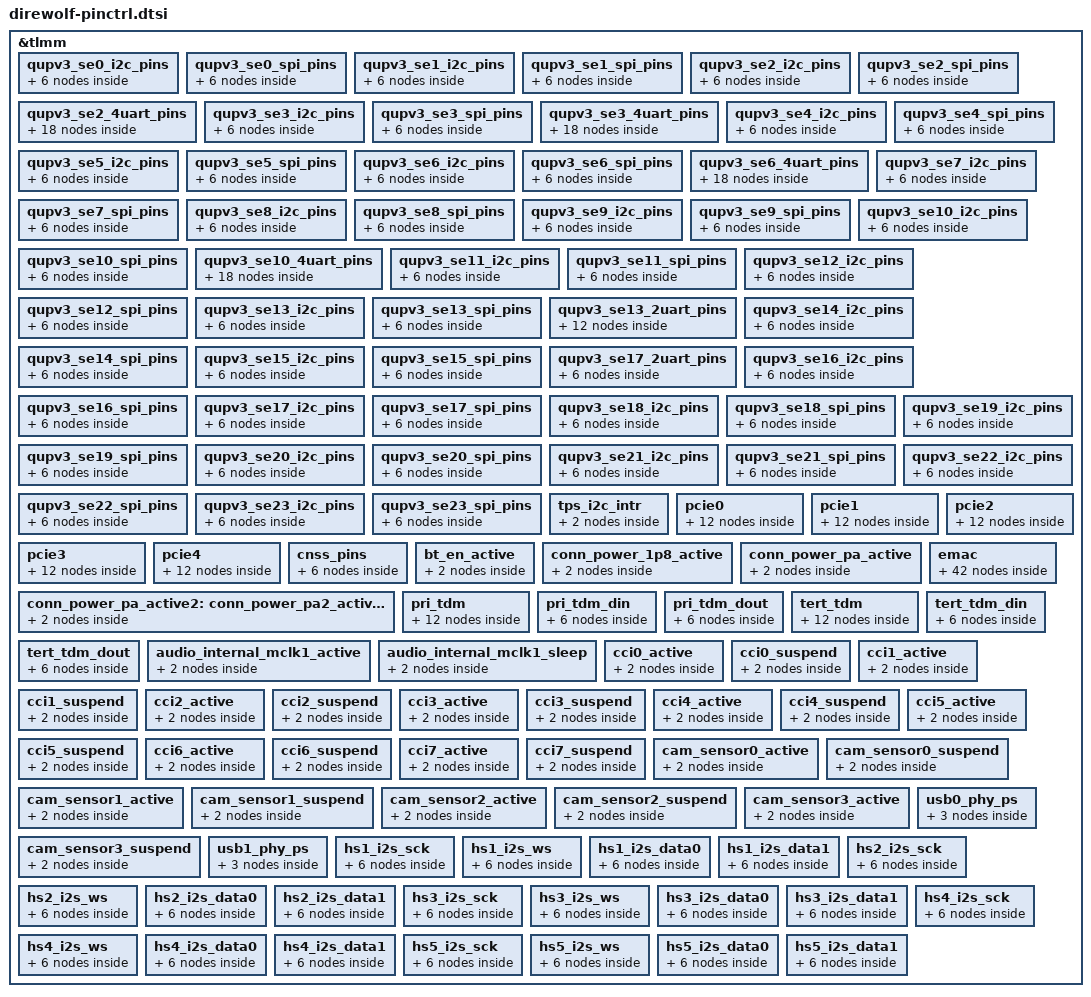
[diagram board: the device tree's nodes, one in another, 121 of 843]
&tlmm {
	qupv3_se0_i2c_pins: qupv3_se0_i2c_pins {
		qupv3_se0_i2c_active: qupv3_se0_i2c_active {
			mux {
				pins = "gpio135", "gpio136";
				function = "qup0";
			};

			config {
				pins = "gpio135", "gpio136";
				drive-strength = <2>;
				bias-pull-up;
			};
		};

		qupv3_se0_i2c_sleep: qupv3_se0_i2c_sleep {
			mux {
				pins = "gpio135", "gpio136";
				function = "gpio";
			};

			config {
				pins = "gpio135", "gpio136";
				drive-strength = <2>;
				bias-disable;
			};
		};
	};

	qupv3_se0_spi_pins: qupv3_se0_spi_pins {
		qupv3_se0_spi_active: qupv3_se0_spi_active {
			mux {
				pins = "gpio135", "gpio136",
						"gpio137", "gpio138";
				function = "qup0";
			};

			config {
				pins = "gpio135", "gpio136",
						"gpio137", "gpio138";
				drive-strength = <6>;
				bias-disable;
			};
		};

		qupv3_se0_spi_sleep: qupv3_se0_spi_sleep {
			mux {
				pins = "gpio135", "gpio136",
						"gpio137", "gpio138";
				function = "gpio";
			};

			config {
				pins = "gpio135", "gpio136",
						"gpio137", "gpio138";
				drive-strength = <6>;
				bias-disable;
			};
		};
	};

	qupv3_se1_i2c_pins: qupv3_se1_i2c_pins {
		qupv3_se1_i2c_active: qupv3_se1_i2c_active {
			mux {
				pins = "gpio158", "gpio159";
				function = "qup1";
			};

			config {
				pins = "gpio158", "gpio159";
				drive-strength = <2>;
				bias-pull-up;
			};
		};

		qupv3_se1_i2c_sleep: qupv3_se1_i2c_sleep {
			mux {
				pins = "gpio158", "gpio159";
				function = "gpio";
			};

			config {
				pins = "gpio158", "gpio159";
				drive-strength = <2>;
				bias-disable;
			};
		};
	};

	qupv3_se1_spi_pins: qupv3_se1_spi_pins {
		qupv3_se1_spi_active: qupv3_se1_spi_active {
			mux {
				pins = "gpio158", "gpio159",
						"gpio160", "gpio161";
				function = "qup1";
			};

			config {
				pins = "gpio158", "gpio159",
						"gpio160", "gpio161";
				drive-strength = <6>;
				bias-disable;
			};
		};

		qupv3_se1_spi_sleep: qupv3_se1_spi_sleep {
			mux {
				pins = "gpio158", "gpio159",
						"gpio160", "gpio161";
				function = "gpio";
			};

			config {
				pins = "gpio158", "gpio159",
						"gpio160", "gpio161";
				drive-strength = <6>;
				bias-disable;
			};
		};
	};

	qupv3_se2_i2c_pins: qupv3_se2_i2c_pins {
		qupv3_se2_i2c_active: qupv3_se2_i2c_active {
			mux {
				pins = "gpio121", "gpio122";
				function = "qup2";
			};

			config {
				pins = "gpio121", "gpio122";
				drive-strength = <2>;
				bias-pull-up;
			};
		};

		qupv3_se2_i2c_sleep: qupv3_se2_i2c_sleep {
			mux {
				pins = "gpio121", "gpio122";
				function = "gpio";
			};

			config {
				pins = "gpio121", "gpio122";
				drive-strength = <2>;
				bias-disable;
			};
		};
	};

	qupv3_se2_spi_pins: qupv3_se2_spi_pins {
		qupv3_se2_spi_active: qupv3_se2_spi_active {
			mux {
				pins = "gpio121", "gpio122",
						"gpio123", "gpio124";
				function = "qup2";
			};

			config {
				pins = "gpio121", "gpio122",
						"gpio123", "gpio124";
				drive-strength = <6>;
				bias-disable;
			};
		};

		qupv3_se2_spi_sleep: qupv3_se2_spi_sleep {
			mux {
				pins = "gpio121", "gpio122",
						"gpio123", "gpio124";
				function = "gpio";
			};

			config {
				pins = "gpio121", "gpio122",
						"gpio123", "gpio124";
				drive-strength = <6>;
				bias-disable;
			};
		};
	};

	qupv3_se2_4uart_pins: qupv3_se2_4uart_pins {
		qupv3_se2_default_cts:
				qupv3_se2_default_cts {
			mux {
				pins = "gpio121";
				function = "gpio";
			};

			config {
				pins = "gpio121";
				drive-strength = <2>;
				bias-disable;
			};
		};

		qupv3_se2_default_rtsrx:
			qupv3_se2_default_rtsrx {
			mux {
				pins = "gpio122", "gpio124";
				function = "gpio";
			};

			config {
				pins = "gpio122", "gpio124";
				drive-strength = <2>;
				bias-pull-down;
			};
		};

		qupv3_se2_default_tx:
			qupv3_se2_default_tx {
			mux {
				pins = "gpio123";
				function = "gpio";
			};

			config {
				pins = "gpio123";
				drive-strength = <2>;
				bias-pull-up;
			};
		};

		qupv3_se2_ctsrx: qupv3_se2_ctsrx {
			mux {
				pins = "gpio121", "gpio124";
				function = "qup2";
			};

			config {
				pins = "gpio121", "gpio124";
				drive-strength = <2>;
				bias-disable;
			};
		};

		qupv3_se2_rts: qupv3_se2_rts {
			mux {
				pins = "gpio122";
				function = "qup2";
			};

			config {
				pins = "gpio122";
				drive-strength = <2>;
				bias-pull-down;
			};
		};

		qupv3_se2_tx: qupv3_se2_tx {
			mux {
				pins = "gpio123";
				function = "qup2";
			};

			config {
				pins = "gpio123";
				drive-strength = <2>;
				bias-pull-up;
			};
		};
	};

	qupv3_se3_i2c_pins: qupv3_se3_i2c_pins {
		qupv3_se3_i2c_active: qupv3_se3_i2c_active {
			mux {
				pins = "gpio137", "gpio138";
				function = "qup3";
			};

			config {
				pins = "gpio137", "gpio138";
				drive-strength = <2>;
				bias-pull-up;
			};
		};

		qupv3_se3_i2c_sleep: qupv3_se3_i2c_sleep {
			mux {
				pins = "gpio137", "gpio138";
				function = "gpio";
			};

			config {
				pins = "gpio137", "gpio138";
				drive-strength = <2>;
				bias-disable;
			};
		};
	};

	qupv3_se3_spi_pins: qupv3_se3_spi_pins {
		qupv3_se3_spi_active: qupv3_se3_spi_active {
			mux {
				pins = "gpio137", "gpio138",
						"gpio135", "gpio136";
				function = "qup3";
			};

			config {
				pins = "gpio137", "gpio138",
						"gpio135", "gpio136";
				drive-strength = <6>;
				bias-disable;
			};
		};

		qupv3_se3_spi_sleep: qupv3_se3_spi_sleep {
			mux {
				pins = "gpio137", "gpio138",
						"gpio135", "gpio136";
				function = "gpio";
			};

			config {
				pins = "gpio137", "gpio138",
						"gpio135", "gpio136";
				drive-strength = <6>;
				bias-disable;
			};
		};
	};

	qupv3_se3_4uart_pins: qupv3_se3_4uart_pins {
		qupv3_se3_default_cts:
				qupv3_se3_default_cts {
			mux {
				pins = "gpio137";
				function = "gpio";
			};

			config {
				pins = "gpio137";
				drive-strength = <2>;
				bias-disable;
			};
		};

		qupv3_se3_default_rtsrx:
			qupv3_se3_default_rtsrx {
			mux {
				pins = "gpio138", "gpio136";
				function = "gpio";
			};

			config {
				pins = "gpio138", "gpio136";
				drive-strength = <2>;
				bias-pull-down;
			};
		};

		qupv3_se3_default_tx:
			qupv3_se3_default_tx {
			mux {
				pins = "gpio135";
				function = "gpio";
			};

			config {
				pins = "gpio135";
				drive-strength = <2>;
				bias-pull-up;
			};
		};

		qupv3_se3_ctsrx: qupv3_se3_ctsrx {
			mux {
				pins = "gpio137", "gpio136";
				function = "qup2";
			};

			config {
				pins = "gpio137", "gpio136";
				drive-strength = <2>;
				bias-disable;
			};
		};

		qupv3_se3_rts: qupv3_se3_rts {
			mux {
				pins = "gpio138";
				function = "qup2";
			};

			config {
				pins = "gpio138";
				drive-strength = <2>;
				bias-pull-down;
			};
		};

		qupv3_se3_tx: qupv3_se3_tx {
			mux {
				pins = "gpio135";
				function = "qup2";
			};

			config {
				pins = "gpio135";
				drive-strength = <2>;
				bias-pull-up;
			};
		};
	};

	qupv3_se4_i2c_pins: qupv3_se4_i2c_pins {
		qupv3_se4_i2c_active: qupv3_se4_i2c_active {
			mux {
				pins = "gpio171", "gpio172";
				function = "qup4";
			};

			config {
				pins = "gpio171", "gpio172";
				drive-strength = <2>;
				bias-pull-up;
			};
		};

		qupv3_se4_i2c_sleep: qupv3_se4_i2c_sleep {
			mux {
				pins = "gpio171", "gpio172";
				function = "gpio";
			};

			config {
				pins = "gpio171", "gpio172";
				drive-strength = <2>;
				bias-disable;
			};
		};
	};

	qupv3_se4_spi_pins: qupv3_se4_spi_pins {
		qupv3_se4_spi_active: qupv3_se4_spi_active {
			mux {
				pins = "gpio171", "gpio172",
						"gpio173", "gpio174";
				function = "qup4";
			};

			config {
				pins = "gpio171", "gpio172",
						"gpio173", "gpio174";
				drive-strength = <6>;
				bias-disable;
			};
		};

		qupv3_se4_spi_sleep: qupv3_se4_spi_sleep {
			mux {
				pins = "gpio171", "gpio172",
						"gpio173", "gpio174";
				function = "gpio";
			};

			config {
				pins = "gpio171", "gpio172",
						"gpio173", "gpio174";
				drive-strength = <6>;
				bias-disable;
			};
		};
	};

	qupv3_se5_i2c_pins: qupv3_se5_i2c_pins {
		qupv3_se5_i2c_active: qupv3_se5_i2c_active {
			mux {
				pins = "gpio111", "gpio112";
				function = "qup5";
			};

			config {
				pins = "gpio111", "gpio112";
				drive-strength = <2>;
				bias-pull-up;
			};
		};

		qupv3_se5_i2c_sleep: qupv3_se5_i2c_sleep {
			mux {
				pins = "gpio111", "gpio112";
				function = "gpio";
			};

			config {
				pins = "gpio111", "gpio112";
				drive-strength = <2>;
				bias-disable;
			};
		};
	};

	qupv3_se5_spi_pins: qupv3_se5_spi_pins {
		qupv3_se5_spi_active: qupv3_se5_spi_active {
			mux {
				pins = "gpio111", "gpio112",
						"gpio145", "gpio146";
				function = "qup5";
			};

			config {
				pins = "gpio111", "gpio112",
						"gpio145", "gpio146";
				drive-strength = <6>;
				bias-disable;
			};
		};

		qupv3_se5_spi_sleep: qupv3_se5_spi_sleep {
			mux {
				pins = "gpio111", "gpio112",
						"gpio145", "gpio146";
				function = "gpio";
			};

			config {
				pins = "gpio111", "gpio112",
						"gpio145", "gpio146";
				drive-strength = <6>;
				bias-disable;
			};
		};
	};

	qupv3_se6_i2c_pins: qupv3_se6_i2c_pins {
		qupv3_se6_i2c_active: qupv3_se6_i2c_active {
			mux {
				pins = "gpio154", "gpio155";
				function = "qup6";
			};

			config {
				pins = "gpio154", "gpio155";
				drive-strength = <2>;
				bias-pull-up;
			};
		};

		qupv3_se6_i2c_sleep: qupv3_se6_i2c_sleep {
			mux {
				pins = "gpio154", "gpio155";
				function = "gpio";
			};

			config {
				pins = "gpio154", "gpio155";
				drive-strength = <2>;
				bias-disable;
			};
		};
	};

	qupv3_se6_spi_pins: qupv3_se6_spi_pins {
		qupv3_se6_spi_active: qupv3_se6_spi_active {
			mux {
				pins = "gpio154", "gpio155",
						"gpio156", "gpio157";
				function = "qup6";
			};

			config {
				pins = "gpio154", "gpio155",
						"gpio156", "gpio157";
				drive-strength = <6>;
				bias-disable;
			};
		};

		qupv3_se6_spi_sleep: qupv3_se6_spi_sleep {
			mux {
				pins = "gpio154", "gpio155",
						"gpio156", "gpio157";
				function = "gpio";
			};

			config {
				pins = "gpio154", "gpio155",
						"gpio156", "gpio157";
				drive-strength = <6>;
				bias-disable;
			};
		};
	};

	qupv3_se6_4uart_pins: qupv3_se6_4uart_pins {
		qupv3_se6_default_cts:
			qupv3_se6_default_cts {
			mux {
				pins = "gpio154";
				function = "gpio";
			};

			config {
				pins = "gpio154";
				drive-strength = <2>;
				bias-disable;
			};
		};

		qupv3_se6_default_rtsrx:
			qupv3_se6_default_rtsrx {
			mux {
				pins = "gpio155", "gpio157";
				function = "gpio";
			};

			config {
				pins = "gpio155", "gpio157";
				drive-strength = <2>;
				bias-pull-down;
			};
		};

		qupv3_se6_default_tx:
			qupv3_se6_default_tx {
			mux {
				pins = "gpio156";
				function = "gpio";
			};

			config {
				pins = "gpio156";
				drive-strength = <2>;
				bias-pull-up;
			};
		};

		qupv3_se6_ctsrx: qupv3_se6_ctsrx {
			mux {
				pins = "gpio154", "gpio157";
				function = "qup6";
			};

			config {
				pins = "gpio154", "gpio157";
				drive-strength = <2>;
				bias-disable;
			};
		};

		qupv3_se6_rts: qupv3_se6_rts {
			mux {
				pins = "gpio155";
				function = "qup6";
			};

			config {
				pins = "gpio155";
				drive-strength = <2>;
				bias-pull-down;
			};
		};

		qupv3_se6_tx: qupv3_se6_tx {
			mux {
				pins = "gpio156";
				function = "qup6";
			};

			config {
				pins = "gpio156";
				drive-strength = <2>;
				bias-pull-up;
			};
		};
	};

	qupv3_se7_i2c_pins: qupv3_se7_i2c_pins {
		qupv3_se7_i2c_active: qupv3_se7_i2c_active {
			mux {
				pins = "gpio128", "gpio129";
				function = "qup7";
			};

			config {
				pins = "gpio128", "gpio129";
				drive-strength = <2>;
				bias-pull-up;
			};
		};

		qupv3_se7_i2c_sleep: qupv3_se7_i2c_sleep {
			mux {
				pins = "gpio128", "gpio129";
				function = "gpio";
			};

			config {
				pins = "gpio128", "gpio129";
				drive-strength = <2>;
				bias-disable;
			};
		};
	};

	qupv3_se7_spi_pins: qupv3_se7_spi_pins {
		qupv3_se7_spi_active: qupv3_se7_spi_active {
			mux {
				pins = "gpio128", "gpio129",
						"gpio125", "gpio126";
				function = "qup7";
			};

			config {
				pins = "gpio128", "gpio129",
						"gpio125", "gpio126";
				drive-strength = <6>;
				bias-disable;
			};
		};

		qupv3_se7_spi_sleep: qupv3_se7_spi_sleep {
			mux {
				pins = "gpio128", "gpio129",
						"gpio125", "gpio126";
				function = "gpio";
			};

			config {
				pins = "gpio128", "gpio129",
						"gpio125", "gpio126";
				drive-strength = <6>;
				bias-disable;
			};
		};
	};

	qupv3_se8_i2c_pins: qupv3_se8_i2c_pins {
		qupv3_se8_i2c_active: qupv3_se8_i2c_active {
			mux {
				pins = "gpio43", "gpio44";
				function = "qup8";
			};

			config {
				pins = "gpio43", "gpio44";
				drive-strength = <2>;
				bias-pull-up;
			};
		};

		qupv3_se8_i2c_sleep: qupv3_se8_i2c_sleep {
			mux {
				pins = "gpio43", "gpio44";
				function = "gpio";
			};

			config {
				pins = "gpio43", "gpio44";
				drive-strength = <2>;
				bias-disable;
			};
		};
	};

	qupv3_se8_spi_pins: qupv3_se8_spi_pins {
		qupv3_se8_spi_active: qupv3_se8_spi_active {
			mux {
				pins = "gpio43", "gpio44",
						"gpio45", "gpio46";
				function = "qup8";
			};

			config {
				pins = "gpio43", "gpio44",
						"gpio45", "gpio46";
				drive-strength = <6>;
				bias-disable;
			};
		};

		qupv3_se8_spi_sleep: qupv3_se8_spi_sleep {
			mux {
				pins = "gpio43", "gpio44",
						"gpio45", "gpio46";
				function = "gpio";
			};

			config {
				pins = "gpio43", "gpio44",
						"gpio45", "gpio46";
				drive-strength = <6>;
				bias-disable;
			};
		};
	};

	qupv3_se9_i2c_pins: qupv3_se9_i2c_pins {
		qupv3_se9_i2c_active: qupv3_se9_i2c_active {
			mux {
				pins = "gpio41", "gpio42";
				function = "qup9";
			};

			config {
				pins = "gpio41", "gpio42";
				drive-strength = <2>;
				bias-pull-up;
			};
		};

		qupv3_se9_i2c_sleep: qupv3_se9_i2c_sleep {
			mux {
				pins = "gpio41", "gpio42";
				function = "gpio";
			};

			config {
				pins = "gpio41", "gpio42";
				drive-strength = <2>;
				bias-disable;
			};
		};
	};

	qupv3_se9_spi_pins: qupv3_se9_spi_pins {
		qupv3_se9_spi_active: qupv3_se9_spi_active {
			mux {
				pins = "gpio41", "gpio42",
						"gpio43", "gpio44";
				function = "qup9";
			};

			config {
				pins = "gpio41", "gpio42",
						"gpio43", "gpio44";
				drive-strength = <6>;
				bias-disable;
			};
		};

		qupv3_se9_spi_sleep: qupv3_se9_spi_sleep {
			mux {
				pins = "gpio41", "gpio42",
						"gpio43", "gpio44";
				function = "gpio";
			};

			config {
				pins = "gpio41", "gpio42",
						"gpio43", "gpio44";
				drive-strength = <6>;
				bias-disable;
			};
		};
	};

	qupv3_se10_i2c_pins: qupv3_se10_i2c_pins {
		qupv3_se10_i2c_active: qupv3_se10_i2c_active {
			mux {
				pins = "gpio22", "gpio23";
				function = "qup10";
			};

			config {
				pins = "gpio22", "gpio23";
				drive-strength = <2>;
				bias-pull-up;
			};
		};

		qupv3_se10_i2c_sleep: qupv3_se10_i2c_sleep {
			mux {
				pins = "gpio22", "gpio23";
				function = "gpio";
			};

			config {
				pins = "gpio22", "gpio23";
				drive-strength = <2>;
				bias-disable;
			};
		};
	};

	qupv3_se10_spi_pins: qupv3_se10_spi_pins {
		qupv3_se10_spi_active: qupv3_se10_spi_active {
			mux {
				pins = "gpio22", "gpio23",
						"gpio24", "gpio25";
				function = "qup10";
			};

			config {
				pins = "gpio22", "gpio23",
						"gpio24", "gpio25";
				drive-strength = <6>;
				bias-disable;
			};
		};

		qupv3_se10_spi_sleep: qupv3_se10_spi_sleep {
			mux {
				pins = "gpio22", "gpio23",
						"gpio24", "gpio25";
				function = "gpio";
			};

			config {
				pins = "gpio22", "gpio23",
						"gpio24", "gpio25";
				drive-strength = <6>;
				bias-disable;
			};
		};
	};

	qupv3_se10_4uart_pins: qupv3_se10_4uart_pins {
		qupv3_se10_default_cts:
				qupv3_se10_default_cts {
			mux {
				pins = "gpio22";
				function = "gpio";
			};

			config {
				pins = "gpio22";
				drive-strength = <2>;
				bias-disable;
			};
		};

		qupv3_se10_default_rtsrx:
			qupv3_se10_default_rtsrx {
			mux {
				pins = "gpio23", "gpio25";
				function = "gpio";
			};

			config {
				pins = "gpio23", "gpio25";
				drive-strength = <2>;
				bias-pull-down;
			};
		};

		qupv3_se10_default_tx:
			qupv3_se10_default_tx {
			mux {
				pins = "gpio24";
				function = "gpio";
			};

			config {
				pins = "gpio24";
				drive-strength = <2>;
				bias-pull-up;
			};
		};

		qupv3_se10_ctsrx: qupv3_se10_ctsrx {
			mux {
				pins = "gpio22", "gpio25";
				function = "qup10";
			};

			config {
				pins = "gpio22", "gpio25";
				drive-strength = <2>;
				bias-disable;
			};
		};

		qupv3_se10_rts: qupv3_se10_rts {
			mux {
				pins = "gpio23";
				function = "qup10";
			};

			config {
				pins = "gpio23";
				drive-strength = <2>;
				bias-pull-down;
			};
		};

		qupv3_se10_tx: qupv3_se10_tx {
			mux {
				pins = "gpio24";
				function = "qup10";
			};

			config {
				pins = "gpio24";
				drive-strength = <2>;
				bias-pull-up;
			};
		};
	};

	qupv3_se11_i2c_pins: qupv3_se11_i2c_pins {
		qupv3_se11_i2c_active: qupv3_se11_i2c_active {
			mux {
				pins = "gpio18", "gpio19";
				function = "qup11";
			};

			config {
				pins = "gpio18", "gpio19";
				drive-strength = <2>;
				bias-pull-up;
			};
		};

		qupv3_se11_i2c_sleep: qupv3_se11_i2c_sleep {
			mux {
				pins = "gpio18", "gpio19";
				function = "gpio";
			};

			config {
				pins = "gpio18", "gpio19";
				drive-strength = <2>;
				bias-disable;
			};
		};
	};

	qupv3_se11_spi_pins: qupv3_se11_spi_pins {
		qupv3_se11_spi_active: qupv3_se11_spi_active {
			mux {
				pins = "gpio18", "gpio19",
						"gpio20", "gpio21";
				function = "qup11";
			};

			config {
				pins = "gpio18", "gpio19",
						"gpio20", "gpio21";
				drive-strength = <6>;
				bias-disable;
			};
		};

		qupv3_se11_spi_sleep: qupv3_se11_spi_sleep {
			mux {
				pins = "gpio18", "gpio19",
						"gpio20", "gpio21";
				function = "gpio";
			};

			config {
				pins = "gpio18", "gpio19",
						"gpio20", "gpio21";
				drive-strength = <6>;
				bias-disable;
			};
		};
	};

	qupv3_se12_i2c_pins: qupv3_se12_i2c_pins {
		qupv3_se12_i2c_active: qupv3_se12_i2c_active {
			mux {
				pins = "gpio0", "gpio1";
				function = "qup12";
			};

			config {
				pins = "gpio0", "gpio1";
				drive-strength = <2>;
				bias-pull-up;
			};
		};

		qupv3_se12_i2c_sleep: qupv3_se12_i2c_sleep {
			mux {
				pins = "gpio0", "gpio1";
				function = "gpio";
			};

			config {
				pins = "gpio0", "gpio1";
				drive-strength = <2>;
				bias-disable;
			};
		};
	};

	qupv3_se12_spi_pins: qupv3_se12_spi_pins {
		qupv3_se12_spi_active: qupv3_se12_spi_active {
			mux {
				pins = "gpio0", "gpio1",
						"gpio2", "gpio3";
				function = "qup12";
			};

			config {
				pins = "gpio0", "gpio1",
						"gpio2", "gpio3";
				drive-strength = <6>;
				bias-disable;
			};
		};

		qupv3_se12_spi_sleep: qupv3_se12_spi_sleep {
			mux {
				pins = "gpio0", "gpio1",
						"gpio2", "gpio3";
				function = "gpio";
			};

			config {
				pins = "gpio0", "gpio1",
						"gpio2", "gpio3";
				drive-strength = <6>;
				bias-disable;
			};
		};
	};

	qupv3_se13_i2c_pins: qupv3_se13_i2c_pins {
		qupv3_se13_i2c_active: qupv3_se13_i2c_active {
			mux {
				pins = "gpio26", "gpio27";
				function = "qup13";
			};

			config {
				pins = "gpio26", "gpio27";
				drive-strength = <2>;
				bias-pull-up;
			};
		};

		qupv3_se13_i2c_sleep: qupv3_se13_i2c_sleep {
			mux {
				pins = "gpio26", "gpio27";
				function = "gpio";
			};

			config {
				pins = "gpio26", "gpio27";
				drive-strength = <2>;
				bias-disable;
			};
		};
	};

	qupv3_se13_spi_pins: qupv3_se13_spi_pins {
		qupv3_se13_spi_active: qupv3_se13_spi_active {
			mux {
				pins = "gpio26", "gpio27",
						"gpio28", "gpio29";
				function = "qup13";
			};

			config {
				pins = "gpio26", "gpio27",
						"gpio28", "gpio29";
				drive-strength = <6>;
				bias-disable;
			};
		};

		qupv3_se13_spi_sleep: qupv3_se13_spi_sleep {
			mux {
				pins = "gpio26", "gpio27",
						"gpio28", "gpio29";
				function = "gpio";
			};

			config {
				pins = "gpio26", "gpio27",
						"gpio28", "gpio29";
				drive-strength = <6>;
				bias-disable;
			};
		};
	};

	qupv3_se13_2uart_pins: qupv3_se13_2uart_pins {
		qupv3_se13_2uart_default: qupv3_se13_2uart_default {
			mux {
				pins = "gpio28", "gpio29";
				function = "qup13";
			};

			config {
				pins = "gpio28", "gpio29";
				drive-strength = <6>;
				bias-disable;
			};
		};

		qupv3_se13_2uart_active: qupv3_se13_2uart_active {
			mux {
				pins = "gpio28", "gpio29";
				function = "qup13";
			};

			config {
				pins = "gpio28", "gpio29";
				drive-strength = <6>;
				bias-disable;
			};
		};

		qupv3_se13_2uart_sleep: qupv3_se13_2uart_sleep {
			mux {
				pins = "gpio28", "gpio29";
				function = "gpio";
			};

			config {
				pins = "gpio28", "gpio29";
				drive-strength = <2>;
				bias-disable;
			};
		};

		 qupv3_se13_2uart_disable: qupv3_se13_2uart_disable {
			rtr {
				pins = "gpio27";
				drive-strength = <2>;
				bias-disable;
				input-enable;
			};

			cts {
				pins = "gpio26";
				drive-strength = <0>;
				bias-pull-up;
			};
		};
	};

	qupv3_se14_i2c_pins: qupv3_se14_i2c_pins {
		qupv3_se14_i2c_active: qupv3_se14_i2c_active {
			mux {
				pins = "gpio4", "gpio5";
				function = "qup14";
			};

			config {
				pins = "gpio4", "gpio5";
				drive-strength = <2>;
				bias-pull-up;
			};
		};

		qupv3_se14_i2c_sleep: qupv3_se14_i2c_sleep {
			mux {
				pins = "gpio4", "gpio5";
				function = "gpio";
			};

			config {
				pins = "gpio4", "gpio5";
				drive-strength = <2>;
				bias-disable;
			};
		};
	};

	qupv3_se14_spi_pins: qupv3_se14_spi_pins {
		qupv3_se14_spi_active: qupv3_se14_spi_active {
			mux {
				pins = "gpio4", "gpio5",
						"gpio6", "gpio7";
				function = "qup14";
			};

			config {
				pins = "gpio4", "gpio5",
						"gpio6", "gpio7";
				drive-strength = <6>;
				bias-disable;
			};
		};

		qupv3_se14_spi_sleep: qupv3_se14_spi_sleep {
			mux {
				pins = "gpio4", "gpio5",
						"gpio6", "gpio7";
				function = "gpio";
			};

			config {
				pins = "gpio4", "gpio5",
						"gpio6", "gpio7";
				drive-strength = <6>;
				bias-disable;
			};
		};
	};

	qupv3_se15_i2c_pins: qupv3_se15_i2c_pins {
		qupv3_se15_i2c_active: qupv3_se15_i2c_active {
			mux {
				pins = "gpio36", "gpio37";
				function = "qup15";
			};

			config {
				pins = "gpio36", "gpio37";
				drive-strength = <2>;
				bias-pull-up;
			};
		};

		qupv3_se15_i2c_sleep: qupv3_se15_i2c_sleep {
			mux {
				pins = "gpio36", "gpio37";
				function = "gpio";
			};

			config {
				pins = "gpio36", "gpio37";
				drive-strength = <2>;
				bias-disable;
			};
		};
	};

	qupv3_se15_spi_pins: qupv3_se15_spi_pins {
		qupv3_se15_spi_active: qupv3_se15_spi_active {
			mux {
				pins = "gpio36", "gpio37",
						"gpio38", "gpio39";
				function = "qup15";
			};

			config {
				pins = "gpio36", "gpio37",
						"gpio38", "gpio39";
				drive-strength = <6>;
				bias-disable;
			};
		};

		qupv3_se15_spi_sleep: qupv3_se15_spi_sleep {
			mux {
				pins = "gpio36", "gpio37",
						"gpio38", "gpio39";
				function = "gpio";
			};

			config {
				pins = "gpio36", "gpio37",
						"gpio38", "gpio39";
				drive-strength = <6>;
				bias-disable;
			};
		};
	};

	qupv3_se17_2uart_pins: qupv3_se17_2uart_pins {
		qupv3_se17_2uart_active: qupv3_se17_2uart_active {
			mux {
				pins = "gpio63", "gpio64";
				function = "qup17";
			};

			config {
				pins = "gpio63", "gpio64";
				drive-strength = <2>;
				bias-disable;
			};
		};

		qupv3_se17_2uart_sleep: qupv3_se17_2uart_sleep {
			mux {
				pins = "gpio63", "gpio64";
				function = "gpio";
			};

			config {
				pins = "gpio63", "gpio64";
				drive-strength = <2>;
				bias-pull-down;
			};
		};
	};

	qupv3_se16_i2c_pins: qupv3_se16_i2c_pins {
		qupv3_se16_i2c_active: qupv3_se16_i2c_active {
			mux {
				pins = "gpio70", "gpio71";
				function = "qup16";
			};

			config {
				pins = "gpio70", "gpio71";
				drive-strength = <2>;
				bias-pull-up;
			};
		};

		qupv3_se16_i2c_sleep: qupv3_se16_i2c_sleep {
			mux {
				pins = "gpio70", "gpio71";
				function = "gpio";
			};

			config {
				pins = "gpio70", "gpio71";
				drive-strength = <2>;
				bias-disable;
			};
		};
	};

	qupv3_se16_spi_pins: qupv3_se16_spi_pins {
		qupv3_se16_spi_active: qupv3_se16_spi_active {
			mux {
				pins = "gpio70", "gpio71",
						"gpio72", "gpio73";
				function = "qup16";
			};

			config {
				pins = "gpio70", "gpio71",
						"gpio72", "gpio73";
				drive-strength = <6>;
				bias-disable;
			};
		};

		qupv3_se16_spi_sleep: qupv3_se16_spi_sleep {
			mux {
				pins = "gpio70", "gpio71",
						"gpio72", "gpio73";
				function = "gpio";
			};

			config {
				pins = "gpio70", "gpio71",
						"gpio72", "gpio73";
				drive-strength = <6>;
				bias-disable;
			};
		};
	};

	qupv3_se17_i2c_pins: qupv3_se17_i2c_pins {
		qupv3_se17_i2c_active: qupv3_se17_i2c_active {
			mux {
				pins = "gpio61", "gpio62";
				function = "qup17";
			};

			config {
				pins = "gpio61", "gpio62";
				drive-strength = <2>;
				bias-pull-up;
			};
		};

		qupv3_se17_i2c_sleep: qupv3_se17_i2c_sleep {
			mux {
				pins = "gpio61", "gpio62";
				function = "gpio";
			};

			config {
				pins = "gpio61", "gpio62";
				drive-strength = <2>;
				bias-disable;
			};
		};
	};

	qupv3_se17_spi_pins: qupv3_se17_spi_pins {
		qupv3_se17_spi_active: qupv3_se17_spi_active {
			mux {
				pins = "gpio61", "gpio62",
						"gpio63", "gpio64";
				function = "qup17";
			};

			config {
				pins = "gpio61", "gpio62",
						"gpio63", "gpio64";
				drive-strength = <6>;
				bias-disable;
			};
		};

		qupv3_se17_spi_sleep: qupv3_se17_spi_sleep {
			mux {
				pins = "gpio61", "gpio62",
						"gpio63", "gpio64";
				function = "gpio";
			};

			config {
				pins = "gpio61", "gpio62",
						"gpio63", "gpio64";
				drive-strength = <6>;
				bias-disable;
			};
		};
	};

	qupv3_se18_i2c_pins: qupv3_se18_i2c_pins {
		qupv3_se18_i2c_active: qupv3_se18_i2c_active {
			mux {
				pins = "gpio66", "gpio67";
				function = "qup18";
			};

			config {
				pins = "gpio66", "gpio67";
				drive-strength = <2>;
				bias-pull-up;
			};
		};

		qupv3_se18_i2c_sleep: qupv3_se18_i2c_sleep {
			mux {
				pins = "gpio66", "gpio67";
				function = "gpio";
			};

			config {
				pins = "gpio66", "gpio67";
				drive-strength = <2>;
				bias-disable;
			};
		};
	};

	qupv3_se18_spi_pins: qupv3_se18_spi_pins {
		qupv3_se18_spi_active: qupv3_se18_spi_active {
			mux {
				pins = "gpio66", "gpio67",
						"gpio68", "gpio69";
				function = "qup18";
			};

			config {
				pins = "gpio66", "gpio67",
						"gpio68", "gpio69";
				drive-strength = <6>;
				bias-disable;
			};
		};

		qupv3_se18_spi_sleep: qupv3_se18_spi_sleep {
			mux {
				pins = "gpio66", "gpio67",
						"gpio68", "gpio69";
				function = "gpio";
			};

			config {
				pins = "gpio66", "gpio67",
						"gpio68", "gpio69";
				drive-strength = <6>;
				bias-disable;
			};
		};
	};

	qupv3_se19_i2c_pins: qupv3_se19_i2c_pins {
		qupv3_se19_i2c_active: qupv3_se19_i2c_active {
			mux {
				pins = "gpio55", "gpio56";
				function = "qup19";
			};

			config {
				pins = "gpio55", "gpio56";
				drive-strength = <2>;
				bias-pull-up;
			};
		};

		qupv3_se19_i2c_sleep: qupv3_se19_i2c_sleep {
			mux {
				pins = "gpio55", "gpio56";
				function = "gpio";
			};

			config {
				pins = "gpio55", "gpio56";
				drive-strength = <2>;
				bias-disable;
			};
		};
	};

	qupv3_se19_spi_pins: qupv3_se19_spi_pins {
		qupv3_se19_spi_active: qupv3_se19_spi_active {
			mux {
				pins = "gpio55", "gpio56",
						"gpio57", "gpio58";
				function = "qup19";
			};

			config {
				pins = "gpio55", "gpio56",
						"gpio57", "gpio58";
				drive-strength = <6>;
				bias-disable;
			};
		};

		qupv3_se19_spi_sleep: qupv3_se19_spi_sleep {
			mux {
				pins = "gpio55", "gpio56",
						"gpio57", "gpio58";
				function = "gpio";
			};

			config {
				pins = "gpio55", "gpio56",
						"gpio57", "gpio58";
				drive-strength = <6>;
				bias-disable;
			};
		};
	};

	qupv3_se20_i2c_pins: qupv3_se20_i2c_pins {
		qupv3_se20_i2c_active: qupv3_se20_i2c_active {
			mux {
				pins = "gpio87", "gpio88";
				function = "qup20";
			};

			config {
				pins = "gpio87", "gpio88";
				drive-strength = <2>;
				bias-pull-up;
			};
		};

		qupv3_se20_i2c_sleep: qupv3_se20_i2c_sleep {
			mux {
				pins = "gpio87", "gpio88";
				function = "gpio";
			};

			config {
				pins = "gpio87", "gpio88";
				drive-strength = <2>;
				bias-disable;
			};
		};
	};

	qupv3_se20_spi_pins: qupv3_se20_spi_pins {
		qupv3_se20_spi_active: qupv3_se20_spi_active {
			mux {
				pins = "gpio87", "gpio88",
						"gpio89", "gpio90";
				function = "qup20";
			};

			config {
				pins = "gpio87", "gpio88",
						"gpio89", "gpio90";
				drive-strength = <6>;
				bias-disable;
			};
		};

		qupv3_se20_spi_sleep: qupv3_se20_spi_sleep {
			mux {
				pins = "gpio87", "gpio88",
						"gpio89", "gpio90";
				function = "gpio";
			};

			config {
				pins = "gpio87", "gpio88",
						"gpio89", "gpio90";
				drive-strength = <6>;
				bias-disable;
			};
		};
	};

	qupv3_se21_i2c_pins: qupv3_se21_i2c_pins {
		qupv3_se21_i2c_active: qupv3_se21_i2c_active {
			mux {
				pins = "gpio81", "gpio82";
				function = "qup21";
			};

			config {
				pins = "gpio81", "gpio82";
				drive-strength = <2>;
				bias-pull-up;
			};
		};

		qupv3_se21_i2c_sleep: qupv3_se21_i2c_sleep {
			mux {
				pins = "gpio81", "gpio82";
				function = "gpio";
			};

			config {
				pins = "gpio81", "gpio82";
				drive-strength = <2>;
				bias-disable;
			};
		};
	};

	qupv3_se21_spi_pins: qupv3_se21_spi_pins {
		qupv3_se21_spi_active: qupv3_se21_spi_active {
			mux {
				pins = "gpio81", "gpio82",
						"gpio83", "gpio84";
				function = "qup21";
			};

			config {
				pins = "gpio81", "gpio82",
						"gpio83", "gpio84";
				drive-strength = <6>;
				bias-disable;
			};
		};

		qupv3_se21_spi_sleep: qupv3_se21_spi_sleep {
			mux {
				pins = "gpio81", "gpio82",
						"gpio83", "gpio84";
				function = "gpio";
			};

			config {
				pins = "gpio81", "gpio82",
						"gpio83", "gpio84";
				drive-strength = <6>;
				bias-disable;
			};
		};
	};

	qupv3_se22_i2c_pins: qupv3_se22_i2c_pins {
		qupv3_se22_i2c_active: qupv3_se22_i2c_active {
			mux {
				pins = "gpio85", "gpio85";
				function = "qup22";
			};

			config {
				pins = "gpio85", "gpio85";
				drive-strength = <2>;
				bias-pull-up;
			};
		};

		qupv3_se22_i2c_sleep: qupv3_se22_i2c_sleep {
			mux {
				pins = "gpio85", "gpio85";
				function = "gpio";
			};

			config {
				pins = "gpio85", "gpio85";
				drive-strength = <2>;
				bias-disable;
			};
		};
	};

	qupv3_se22_spi_pins: qupv3_se22_spi_pins {
		qupv3_se22_spi_active: qupv3_se22_spi_active {
			mux {
				pins = "gpio85", "gpio86",
						"gpio83", "gpio84";
				function = "qup22";
			};

			config {
				pins = "gpio85", "gpio86",
						"gpio83", "gpio84";
				drive-strength = <6>;
				bias-disable;
			};
		};

		qupv3_se22_spi_sleep: qupv3_se22_spi_sleep {
			mux {
				pins = "gpio85", "gpio86",
						"gpio83", "gpio84";
				function = "gpio";
			};

			config {
				pins = "gpio85", "gpio86",
						"gpio83", "gpio84";
				drive-strength = <6>;
				bias-disable;
			};
		};
	};

	qupv3_se23_i2c_pins: qupv3_se23_i2c_pins {
		qupv3_se23_i2c_active: qupv3_se23_i2c_active {
			mux {
				pins = "gpio59", "gpio60";
				function = "qup23";
			};

			config {
				pins = "gpio59", "gpio60";
				drive-strength = <2>;
				bias-pull-up;
			};
		};

		qupv3_se23_i2c_sleep: qupv3_se23_i2c_sleep {
			mux {
				pins = "gpio59", "gpio60";
				function = "gpio";
			};

			config {
				pins = "gpio59", "gpio60";
				drive-strength = <2>;
				bias-disable;
			};
		};
	};

	qupv3_se23_spi_pins: qupv3_se23_spi_pins {
		qupv3_se23_spi_active: qupv3_se23_spi_active {
			mux {
				pins = "gpio59", "gpio60",
						"gpio61", "gpio62";
				function = "qup23";
			};

			config {
				pins = "gpio59", "gpio60",
						"gpio61", "gpio62";
				drive-strength = <6>;
				bias-disable;
			};
		};

		qupv3_se23_spi_sleep: qupv3_se23_spi_sleep {
			mux {
				pins = "gpio59", "gpio60",
						"gpio61", "gpio62";
				function = "gpio";
			};

			config {
				pins = "gpio59", "gpio60",
						"gpio61", "gpio62";
				drive-strength = <6>;
				bias-disable;
			};
		};
	};

	tps_i2c_intr: tps_i2c_intr {
		mux {
			pins = "gpio138";
			function = "gpio";
		};

		config {
			pins = "gpio138";
			drive-strength = <2>;
			bias-pull-up;
			input-enable;
		};
	};

	pcie0 {
		pcie2a_perst_default: pcie2a_perst_default {
			mux {
				pins = "gpio143";
				function = "gpio";
			};

			config {
				pins = "gpio143";
				drive-strength = <2>;
				bias-pull-down;
			};
		};

		pcie2a_clkreq_default: pcie2a_clkreq_default {
			mux {
				pins = "gpio142";
				function = "pcie2a_clkreq";
			};

			config {
				pins = "gpio142";
				drive-strength = <2>;
				bias-pull-up;
			};
		};

		pcie2a_wake_default: pcie2a_wake_default {
			mux {
				pins = "gpio145";
				function = "gpio";
			};

			config {
				pins = "gpio145";
				drive-strength = <2>;
				bias-pull-up;
			};
		};

		pcie2a_clkreq_sleep: pcie2a_clkreq_sleep {
			mux {
				pins = "gpio142";
				function = "gpio";
			};

			config {
				pins = "gpio142";
				drive-strength = <2>;
				bias-pull-up;
			};
		};
	};

	pcie1 {
		pcie2b_perst_default: pcie2b_perst_default {
			mux {
				pins = "gpio147";
				function = "gpio";
			};

			config {
				pins = "gpio147";
				drive-strength = <2>;
				bias-pull-down;
			};
		};

		pcie2b_clkreq_default: pcie2b_clkreq_default {
			mux {
				pins = "gpio144";
				function = "pcie2b_clkreq";
			};

			config {
				pins = "gpio144";
				drive-strength = <2>;
				bias-pull-up;
			};
		};

		pcie2b_wake_default: pcie2b_wake_default {
			mux {
				pins = "gpio146";
				function = "gpio";
			};

			config {
				pins = "gpio146";
				drive-strength = <2>;
				bias-pull-up;
			};
		};

		pcie2b_clkreq_sleep: pcie2b_clkreq_sleep {
			mux {
				pins = "gpio144";
				function = "gpio";
			};

			config {
				pins = "gpio144";
				drive-strength = <2>;
				bias-pull-up;
			};
		};
	};

	pcie2 {
		pcie3a_perst_default: pcie3a_perst_default {
			mux {
				pins = "gpio151";
				function = "gpio";
			};

			config {
				pins = "gpio151";
				drive-strength = <2>;
				bias-pull-down;
			};
		};

		pcie3a_clkreq_default: pcie3a_clkreq_default {
			mux {
				pins = "gpio150";
				function = "pcie3a_clkreq";
			};

			config {
				pins = "gpio150";
				drive-strength = <2>;
				bias-pull-up;
			};
		};

		pcie3a_wake_default: pcie3a_wake_default {
			mux {
				pins = "gpio56";
				function = "gpio";
			};

			config {
				pins = "gpio56";
				drive-strength = <2>;
				bias-pull-up;
			};
		};

		pcie3a_clkreq_sleep: pcie3a_clkreq_sleep {
			mux {
				pins = "gpio150";
				function = "gpio";
			};

			config {
				pins = "gpio150";
				drive-strength = <2>;
				bias-pull-up;
			};
		};
	};

	pcie3 {
		pcie3b_perst_default: pcie3b_perst_default {
			mux {
				pins = "gpio153";
				function = "gpio";
			};

			config {
				pins = "gpio153";
				drive-strength = <2>;
				bias-pull-down;
			};
		};

		pcie3b_clkreq_default: pcie3b_clkreq_default {
			mux {
				pins = "gpio152";
				function = "pcie3b_clkreq";
			};

			config {
				pins = "gpio152";
				drive-strength = <2>;
				bias-pull-up;
			};
		};

		pcie3b_wake_default: pcie3b_wake_default {
			mux {
				pins = "gpio130";
				function = "gpio";
			};

			config {
				pins = "gpio130";
				drive-strength = <2>;
				bias-pull-up;
			};
		};

		pcie3b_clkreq_sleep: pcie3b_clkreq_sleep {
			mux {
				pins = "gpio152";
				function = "gpio";
			};

			config {
				pins = "gpio152";
				drive-strength = <2>;
				bias-pull-up;
			};
		};
	};

	pcie4 {
		pcie4_perst_default: pcie4_perst_default {
			mux {
				pins = "gpio141";
				function = "gpio";
			};

			config {
				pins = "gpio141";
				drive-strength = <2>;
				bias-pull-down;
			};
		};

		pcie4_clkreq_default: pcie4_clkreq_default {
			mux {
				pins = "gpio140";
				function = "pcie4_clkreq";
			};

			config {
				pins = "gpio140";
				drive-strength = <2>;
				bias-pull-up;
			};
		};

		pcie4_wake_default: pcie4_wake_default {
			mux {
				pins = "gpio139";
				function = "gpio";
			};

			config {
				pins = "gpio139";
				drive-strength = <2>;
				bias-pull-up;
			};
		};

		pcie4_clkreq_sleep: pcie4_clkreq_sleep {
			mux {
				pins = "gpio140";
				function = "gpio";
			};

			config {
				pins = "gpio140";
				drive-strength = <2>;
				bias-pull-up;
			};
		};
	};

	cnss_pins: cnss_pins {
		cnss_wlan_en_active: cnss_wlan_en_active {
			mux {
				pins = "gpio125";
				function = "gpio";
			};

			config {
				pins = "gpio125";
				drive-strength = <16>;
				output-high;
				bias-pull-up;
			};
		};

		cnss_wlan_en_sleep: cnss_wlan_en_sleep {
			mux {
				pins = "gpio125";
				function = "gpio";
			};

			config {
				pins = "gpio125";
				drive-strength = <2>;
				output-low;
				bias-pull-down;
			};
		};
	};

	bt_en_active: bt_en_active {
		mux {
			pins = "gpio126";
			function = "gpio";
		};

		config {
			pins = "gpio126";
			drive-strength = <2>;
			output-low;
			bias-pull-down;
		};
	};

	conn_power_1p8_active: conn_power_1p8_active {
		mux {
			pins = "gpio128";
			function = "gpio";
		};

		config {
			pins = "gpio128";
			drive-strength = <2>;
			bias-pull-up;
		};
	};

	conn_power_pa_active: conn_power_pa_active {
		mux {
			pins = "gpio129";
			function = "gpio";
		};

		config {
			pins = "gpio129";
			drive-strength = <2>;
			bias-pull-up;
		};
	};

	conn_power_pa_active2: conn_power_pa2_active2 {
		mux {
			pins = "gpio216";
			function = "gpio";
		};

		config {
			pins = "gpio216";
			drive-strength = <2>;
			bias-pull-up;
		};
	};

	emac {
		emac_mdc: emac_mdc {
			mux {
				pins = "gpio175";
				function = "rgmii_0";
			};

			config {
				pins = "gpio175";
				bias-pull-up;
				drive-strength = <16>;
			};
		};

		emac_mdio: emac_mdio {
			mux {
				pins = "gpio176";
				function = "rgmii_0";
			};

			config {
				pins = "gpio176";
				bias-pull-up;
				drive-strength = <16>;
			};
		};

		emac_rgmii_txd0: emac_rgmii_txd0 {
			mux {
				pins = "gpio185";
				function = "rgmii_0";
			};

			config {
				pins = "gpio185";
				bias-pull-up;
				drive-strength = <16>;
			};
		};

		emac_rgmii_txd1: emac_rgmii_txd1 {
			mux {
				pins = "gpio186";
				function = "rgmii_0";
			};

			config {
				pins = "gpio186";
				bias-pull-up;
				drive-strength = <16>;
			};
		};

		emac_rgmii_txd2: emac_rgmii_txd2 {
			mux {
				pins = "gpio187";
				function = "rgmii_0";
			};

			config {
				pins = "gpio187";
				bias-pull-up;
				drive-strength = <16>;
			};
		};

		emac_rgmii_txd3: emac_rgmii_txd3 {
			mux {
				pins = "gpio188";
				function = "rgmii_0";
			};

			config {
				pins = "gpio188";
				bias-pull-up;
				drive-strength = <16>;
			};
		};

		emac_rgmii_txc: emac_rgmii_txc {
			mux {
				pins = "gpio183";
				function = "rgmii_0";
			};

			config {
				pins = "gpio183";
				bias-pull-up;
				drive-strength = <16>;
			};
		};

		emac_rgmii_tx_ctl: emac_rgmii_tx_ctl {
			mux {
				pins = "gpio184";
				function = "rgmii_0";
			};

			config {
				pins = "gpio184";
				bias-pull-up;
				drive-strength = <16>;
			};
		};

		emac_rgmii_rxd0: emac_rgmii_rxd0 {
			mux {
				pins = "gpio179";
				function = "rgmii_0";
			};

			config {
				pins = "gpio179";
				bias-disable;  /* NO pull */
				drive-strength = <16>;  /* 16MA */
			};
		};

		emac_rgmii_rxd1: emac_rgmii_rxd1 {
			mux {
				pins = "gpio180";
				function = "rgmii_0";
			};

			config {
				pins = "gpio180";
				bias-disable;  /* NO pull */
				drive-strength = <16>;
			};
		};

		emac_rgmii_rxd2: emac_rgmii_rxd2 {
			mux {
				pins = "gpio181";
				function = "rgmii_0";
			};

			config {
				pins = "gpio181";
				bias-disable;	/* NO pull */
				drive-strength = <16>;
			};
		};

		emac_rgmii_rxd3: emac_rgmii_rxd3 {
			mux {
				pins = "gpio182";
				function = "rgmii_0";
			};

			config {
				pins = "gpio182";
				bias-disable;	/* NO pull */
				drive-strength = <16>;
			};
		};

		emac_rgmii_rxc: emac_rgmii_rxc {
			mux {
				pins = "gpio177";
				function = "rgmii_0";
			};

			config {
				pins = "gpio177";
				bias-disable;	/* NO pull */
				drive-strength = <16>;
			};
		};

		emac_rgmii_rx_ctl: emac_rgmii_rx_ctl {
			mux {
				pins = "gpio178";
				function = "rgmii_0";
			};

			config {
				pins = "gpio178";
				bias-disable;  /* NO pull */
				drive-strength = <16>;
			};
		};

	};

	pri_tdm {
		pri_tdm_sck_sleep: pri_tdm_sck_sleep {
			mux {
				pins = "gpio93";
				function = "gpio";
			};

			config {
				pins = "gpio93";
				drive-strength = <2>;   /* 2 mA */
				bias-pull-down;         /* PULL DOWN */
				input-enable;
			};
		};

		pri_tdm_sck_active: pri_tdm_sck_active {
			mux {
				pins = "gpio93";
				function = "mi2s0_sck";
			};

			config {
				pins = "gpio93";
				drive-strength = <8>;   /* 8 mA */
				bias-disable;           /* NO PULL */
			};
		};

		pri_tdm_ws_sleep: pri_tdm_ws_sleep {
			mux {
				pins = "gpio94";
				function = "gpio";
			};

			config {
				pins = "gpio94";
				drive-strength = <2>;   /* 2 mA */
				bias-pull-down;         /* PULL DOWN */
				input-enable;
			};
		};

		pri_tdm_ws_active: pri_tdm_ws_active {
			mux {
				pins = "gpio94";
				function = "mi2s0_ws";
			};

			config {
				pins = "gpio94";
				drive-strength = <8>;   /* 8 mA */
				bias-disable;           /* NO PULL */
			};
		};
	};

	pri_tdm_din {
		pri_tdm_din_sleep: pri_tdm_din_sleep {
			mux {
				pins = "gpio95";
				function = "gpio";
			};

			config {
				pins = "gpio95";
				drive-strength = <2>;   /* 2 mA */
				bias-pull-down;         /* PULL DOWN */
				input-enable;
			};
		};

		pri_tdm_din_active: pri_tdm_din_active {
			mux {
				pins = "gpio95";
				function = "mi2s0_data0";
			};

			config {
				pins = "gpio95";
				drive-strength = <8>;   /* 8 mA */
				bias-disable;           /* NO PULL */
			};
		};
	};

	pri_tdm_dout {
		pri_tdm_dout_sleep: pri_tdm_dout_sleep {
			mux {
				pins = "gpio96";
				function = "gpio";
			};

			config {
				pins = "gpio96";
				drive-strength = <2>;   /* 2 mA */
				bias-pull-down;         /* PULL DOWN */
				input-enable;
			};
		};

		pri_tdm_dout_active: pri_tdm_dout_active {
			mux {
				pins = "gpio96";
				function = "mi2s0_data1";
			};

			config {
				pins = "gpio96";
				drive-strength = <8>;   /* 8 mA */
				bias-disable;           /* NO PULL */
				output-high;
			};
		};
	};


	tert_tdm {
		tert_tdm_sck_sleep: tert_tdm_sck_sleep {
			mux {
				pins = "gpio212";
				function = "gpio";
			};

			config {
				pins = "gpio212";
				drive-strength = <2>;   /* 2 mA */
				bias-pull-down;         /* PULL DOWN */
				input-enable;
			};
		};

		tert_tdm_sck_active: tert_tdm_sck_active {
			mux {
				pins = "gpio212";
				function = "mi2s2_sck";
			};

			config {
				pins = "gpio212";
				drive-strength = <8>;   /* 8 mA */
				bias-disable;           /* NO PULL */
			};
		};

		tert_tdm_ws_sleep: tert_tdm_ws_sleep {
			mux {
				pins = "gpio213";
				function = "gpio";
			};

			config {
				pins = "gpio213";
				drive-strength = <2>;   /* 2 mA */
				bias-pull-down;         /* PULL DOWN */
				input-enable;
			};
		};

		tert_tdm_ws_active: tert_tdm_ws_active {
			mux {
				pins = "gpio213";
				function = "mi2s2_ws";
			};

			config {
				pins = "gpio213";
				drive-strength = <8>;   /* 8 mA */
				bias-disable;           /* NO PULL */
			};
		};
	};

	tert_tdm_din {
		tert_tdm_din_sleep: tert_tdm_din_sleep {
			mux {
				pins = "gpio214";
				function = "gpio";
			};

			config {
				pins = "gpio214";
				drive-strength = <2>;   /* 2 mA */
				bias-pull-down;         /* PULL DOWN */
				input-enable;
			};
		};

		tert_tdm_din_active: tert_tdm_din_active {
			mux {
				pins = "gpio214";
				function = "mi2s2_data0";
			};

			config {
				pins = "gpio214";
				drive-strength = <8>;   /* 8 mA */
				bias-disable;           /* NO PULL */
			};
		};
	};

	tert_tdm_dout {
		tert_tdm_dout_sleep: tert_tdm_dout_sleep {
			mux {
				pins = "gpio215";
				function = "gpio";
			};

			config {
				pins = "gpio215";
				drive-strength = <2>;   /* 2 mA */
				bias-pull-down;         /* PULL DOWN */
				input-enable;
			};
		};

		tert_tdm_dout_active: tert_tdm_dout_active {
			mux {
				pins = "gpio215";
				function = "mi2s2_data1";
			};

			config {
				pins = "gpio215";
				drive-strength = <8>;   /* 8 mA */
				bias-disable;           /* NO PULL */
				output-high;
			};
		};
	};

	audio_internal_mclk1_active: audio_internal_mclk1_active {
		mux {
			pins = "gpio80";
			function = "mi2s_mclk1";
		};

		config {
			pins = "gpio80";
			drive-strength = <8>;
			bias-disable;
			output-high;
		};
	};

	audio_internal_mclk1_sleep: audio_internal_mclk1_sleep {
		mux {
			pins = "gpio80";
			function = "gpio";
		};

		config {
			pins = "gpio80";
			drive-strength = <2>;
			bias-pull-down;
		};
	};

	cci0_active: cci0_active {
		mux {
			/* CLK, DATA */
			pins = "gpio113","gpio114";
			function = "cci_i2c";
		};

		config {
			pins = "gpio113","gpio114";
			bias-pull-up; /* PULL UP*/
			drive-strength = <2>; /* 2 MA */
		};
	};

	cci0_suspend: cci0_suspend {
		mux {
			/* CLK, DATA */
			pins = "gpio113","gpio114";
			function = "cci_i2c";
		};

		config {
			pins = "gpio113","gpio114";
			bias-pull-down; /* PULL DOWN */
			drive-strength = <2>; /* 2 MA */
		};
	};

	cci1_active: cci1_active {
		mux {
			/* CLK, DATA */
			pins = "gpio115","gpio116";
			function = "cci_i2c";
		};

		config {
			pins = "gpio115","gpio116";
			bias-pull-up; /* PULL UP*/
			drive-strength = <2>; /* 2 MA */
		};
	};

	cci1_suspend: cci1_suspend {
		mux {
			/* CLK, DATA */
			pins = "gpio115","gpio116";
			function = "cci_i2c";
		};

		config {
			pins = "gpio115","gpio116";
			bias-pull-down; /* PULL DOWN */
			drive-strength = <2>; /* 2 MA */
		};
	};

	cci2_active: cci2_active {
		mux {
			/* CLK, DATA */
			pins = "gpio10","gpio11";
			function = "cci_i2c";
		};

		config {
			pins = "gpio10","gpio11";
			bias-pull-up; /* PULL UP*/
			drive-strength = <2>; /* 2 MA */
		};
	};

	cci2_suspend: cci2_suspend {
		mux {
			/* CLK, DATA */
			pins = "gpio10","gpio11";
			function = "cci_i2c";
		};

		config {
			pins = "gpio10","gpio11";
			bias-pull-down; /* PULL DOWN */
			drive-strength = <2>; /* 2 MA */
		};
	};

	cci3_active: cci3_active {
		mux {
			/* CLK, DATA */
			pins = "gpio123","gpio124";
			function = "cci_i2c";
		};

		config {
			pins = "gpio123","gpio124";
			bias-pull-up; /* PULL UP*/
			drive-strength = <2>; /* 2 MA */
		};
	};

	cci3_suspend: cci3_suspend {
		mux {
			/* CLK, DATA */
			pins = "gpio123","gpio124";
			function = "cci_i2c";
		};

		config {
			pins = "gpio123","gpio124";
			bias-pull-down; /* PULL DOWN */
			drive-strength = <2>; /* 2 MA */
		};
	};

	cci4_active: cci4_active {
		mux {
			/* CLK, DATA */
			pins = "gpio117","gpio118";
			function = "cci_i2c";
		};

		config {
			pins = "gpio117","gpio118";
			bias-pull-up; /* PULL UP*/
			drive-strength = <2>; /* 2 MA */
		};
	};

	cci4_suspend: cci4_suspend {
		mux {
			/* CLK, DATA */
			pins = "gpio117","gpio118";
			function = "cci_i2c";
		};

		config {
			pins = "gpio117","gpio118";
			bias-pull-down; /* PULL DOWN */
			drive-strength = <2>; /* 2 MA */
		};
	};

	cci5_active: cci5_active {
		mux {
			/* CLK, DATA */
			pins = "gpio12","gpio13";
			function = "cci_i2c";
		};

		config {
			pins = "gpio12","gpio13";
			bias-pull-up; /* PULL UP*/
			drive-strength = <2>; /* 2 MA */
		};
	};

	cci5_suspend: cci5_suspend {
		mux {
			/* CLK, DATA */
			pins = "gpio12","gpio13";
			function = "cci_i2c";
		};

		config {
			pins = "gpio12","gpio13";
			bias-pull-down; /* PULL DOWN */
			drive-strength = <2>; /* 2 MA */
		};
	};

	cci6_active: cci6_active {
		mux {
			/* CLK, DATA */
			pins = "gpio145","gpio146";
			function = "cci_i2c";
		};

		config {
			pins = "gpio145","gpio146";
			bias-pull-up; /* PULL UP*/
			drive-strength = <2>; /* 2 MA */
		};
	};

	cci6_suspend: cci6_suspend {
		mux {
			/* CLK, DATA */
			pins = "gpio145","gpio146";
			function = "cci_i2c";
		};

		config {
			pins = "gpio145","gpio146";
			bias-pull-down; /* PULL DOWN */
			drive-strength = <2>; /* 2 MA */
		};
	};

	cci7_active: cci7_active {
		mux {
			/* CLK, DATA */
			pins = "gpio164","gpio165";
			function = "cci_i2c";
		};

		config {
			pins = "gpio164","gpio165";
			bias-pull-up; /* PULL UP*/
			drive-strength = <2>; /* 2 MA */
		};
	};

	cci7_suspend: cci7_suspend {
		mux {
			/* CLK, DATA */
			pins = "gpio164","gpio165";
			function = "cci_i2c";
		};

		config {
			pins = "gpio164","gpio165";
			bias-pull-down; /* PULL DOWN */
			drive-strength = <2>; /* 2 MA */
		};
	};

	cam_sensor0_active: cam_sensor0_active {
		/* intr gpio for bridge chip 0 */
		mux {
			pins = "gpio162";
			function = "gpio";
		};

		config {
			pins = "gpio162";
			bias-pull-up; /* PULL UP */
			drive-strength = <2>; /* 2 MA */
		};
	};

	cam_sensor0_suspend: cam_sensor0_suspend {
		/* intr gpio for bridge chip 0 */
		mux {
			pins = "gpio162";
			function = "gpio";
		};

		config {
			pins = "gpio162";
			bias-pull-down; /* PULL DOWN */
			drive-strength = <2>; /* 2 MA */
		};
	};

	cam_sensor1_active: cam_sensor1_active {
		/* intr gpio for bridge chip 1 */
		mux {
			pins = "gpio163";
			function = "gpio";
		};

		config {
			pins = "gpio163";
			bias-pull-up; /* PULL UP*/
			drive-strength = <2>; /* 2 MA */
		};
	};

	cam_sensor1_suspend: cam_sensor1_suspend {
		/* intr gpio for bridge chip 1 */
		mux {
			pins = "gpio163";
			function = "gpio";
		};

		config {
			pins = "gpio163";
			bias-pull-down; /* PULL DOWN */
			drive-strength = <2>; /* 2 MA */
		};
	};

	cam_sensor2_active: cam_sensor2_active {
		/* intr gpio for bridge chip 2 */
		mux {
			pins = "gpio16";
			function = "gpio";
		};

		config {
			pins = "gpio16";
			bias-pull-up; /* PULL UP */
			drive-strength = <2>; /* 2 MA */
		};
	};

	cam_sensor2_suspend: cam_sensor2_suspend {
		/* intr gpio for bridge chip 2 */
		mux {
			pins = "gpio16";
			function = "gpio";
		};

		config {
			pins = "gpio16";
			bias-pull-down; /* PULL DOWN */
			drive-strength = <2>; /* 2 MA */
		};
	};

	cam_sensor3_active: cam_sensor3_active {
		/* intr gpio for bridge chip 3 */
		mux {
			pins = "gpio17";
			function = "gpio";
		};

		config {
			pins = "gpio17";
			bias-pull-up; /* PULL UP */
			drive-strength = <2>; /* 2 MA */
		};
	};

	cam_sensor3_suspend: cam_sensor3_suspend {
		/* intr gpio for bridge chip 3 */
		mux {
			pins = "gpio17";
			function = "gpio";
		};

		config {
			pins = "gpio17";
			bias-pull-down; /* PULL DOWN */
			drive-strength = <2>; /* 2 MA */
		};
	};

	usb0_phy_ps: usb0_phy_ps {
		usb3phy0_portselect_default: usb3phy0_portselect_default {
			mux {
				pins = "gpio166";
				function = "usb0_phy";
			};

			config {
				pins = "gpio166";
				bias-disable;
				drive-strength = <2>;
			};
		};
	};

	usb1_phy_ps: usb1_phy_ps {
		usb3phy1_portselect_default: usb3phy1_portselect_default {
			mux {
				pins = "gpio49";
				function = "usb1_phy";
			};

			config {
				pins = "gpio49";
				bias-disable;
				drive-strength = <2>;
			};
		};
	};

	hs1_i2s_sck {
		hs1_i2s_sck_sleep: hs1_i2s_sck_sleep {
			mux {
				pins = "gpio208";
				function = "gpio";
			};

			config {
				pins = "gpio208";
				drive-strength = <2>;   /* 2 mA */
				bias-pull-down;         /* PULL DOWN */
				input-enable;
			};
		};

		hs1_i2s_sck_active: hs1_i2s_sck_active {
			mux {
				pins = "gpio208";
				function = "hs1_mi2s";
			};

			config {
				pins = "gpio208";
				drive-strength = <8>;   /* 8 mA */
				bias-disable;           /* NO PULL */
				output-high;
			};
		};
	};

	hs1_i2s_ws {
		hs1_i2s_ws_sleep: hs1_i2s_ws_sleep {
			mux {
				pins = "gpio209";
				function = "gpio";
			};

			config {
				pins = "gpio209";
				drive-strength = <2>;   /* 2 mA */
				bias-pull-down;         /* PULL DOWN */
				input-enable;
			};
		};

		hs1_i2s_ws_active: hs1_i2s_ws_active {
			mux {
				pins = "gpio209";
				function = "hs1_mi2s";
			};

			config {
				pins = "gpio209";
				drive-strength = <8>;   /* 8 mA */
				bias-disable;           /* NO PULL */
				output-high;
			};
		};
	};

	hs1_i2s_data0 {
		hs1_i2s_data0_sleep: hs1_i2s_data0_sleep {
			mux {
				pins = "gpio210";
				function = "gpio";
			};

			config {
				pins = "gpio210";
				drive-strength = <2>;   /* 2 mA */
				bias-pull-down;         /* PULL DOWN */
				input-enable;
			};
		};

		hs1_i2s_data0_active: hs1_i2s_data0_active {
			mux {
				pins = "gpio210";
				function = "hs1_mi2s";
			};

			config {
				pins = "gpio210";
				drive-strength = <8>;   /* 8 mA */
				bias-disable;           /* NO PULL */
				output-high;
			};
		};
	};

	hs1_i2s_data1 {
		hs1_i2s_data1_sleep: hs1_i2s_data1_sleep {
			mux {
				pins = "gpio211";
				function = "gpio";
			};

			config {
				pins = "gpio211";
				drive-strength = <2>;   /* 2 mA */
				bias-pull-down;         /* PULL DOWN */
				input-enable;
			};
		};

		hs1_i2s_data1_active: hs1_i2s_data1_active {
			mux {
				pins = "gpio211";
				function = "hs1_mi2s";
			};

			config {
				pins = "gpio211";
				drive-strength = <8>;   /* 8 mA */
				bias-disable;           /* NO PULL */
				input-enable;
			};
		};
	};

	hs2_i2s_sck {
		hs2_i2s_sck_sleep: hs2_i2s_sck_sleep {
			mux {
				pins = "gpio92";
				function = "gpio";
			};

			config {
				pins = "gpio92";
				drive-strength = <2>;   /* 2 mA */
				bias-pull-down;         /* PULL DOWN */
				input-enable;
			};
		};

		hs2_i2s_sck_active: hs2_i2s_sck_active {
			mux {
				pins = "gpio92";
				function = "hs2_mi2s";
			};

			config {
				pins = "gpio92";
				drive-strength = <8>;   /* 8 mA */
				bias-disable;           /* NO PULL */
				output-high;
			};
		};
	};

	hs2_i2s_ws {
		hs2_i2s_ws_sleep: hs2_i2s_ws_sleep {
			mux {
				pins = "gpio91";
				function = "gpio";
			};

			config {
				pins = "gpio91";
				drive-strength = <2>;   /* 8 mA */
				bias-pull-down;         /* PULL DOWN */
				input-enable;
			};
		};

		hs2_i2s_ws_active: hs2_i2s_ws_active {
			mux {
				pins = "gpio91";
				function = "hs2_mi2s";
			};

			config {
				pins = "gpio91";
				drive-strength = <8>;   /* 8 mA */
				bias-disable;           /* NO PULL */
				output-high;
			};
		};
	};

	hs2_i2s_data0 {
		hs2_i2s_data0_sleep: hs2_i2s_data0_sleep {
			mux {
				pins = "gpio218";
				function = "gpio";
			};

			config {
				pins = "gpio218";
				drive-strength = <2>;   /* 2 mA */
				bias-pull-down;         /* PULL DOWN */
				input-enable;
			};
		};

		hs2_i2s_data0_active: hs2_i2s_data0_active {
			mux {
				pins = "gpio218";
				function = "hs2_mi2s";
			};

			config {
				pins = "gpio218";
				drive-strength = <8>;   /* 8 mA */
				bias-disable;           /* NO PULL */
				output-high;
			};
		};
	};

	hs2_i2s_data1 {
		hs2_i2s_data1_sleep: hs2_i2s_data1_sleep {
			mux {
				pins = "gpio219";
				function = "gpio";
			};

			config {
				pins = "gpio219";
				drive-strength = <2>;   /* 2 mA */
				bias-pull-down;         /* PULL DOWN */
				input-enable;
			};
		};

		hs2_i2s_data1_active: hs2_i2s_data1_active {
			mux {
				pins = "gpio219";
				function = "hs2_mi2s";
			};

			config {
				pins = "gpio219";
				drive-strength = <8>;   /* 8 mA */
				bias-disable;           /* NO PULL */
				input-enable;
			};
		};
	};

	hs3_i2s_sck {
		hs3_i2s_sck_sleep: hs3_i2s_sck_sleep {
			mux {
				pins = "gpio224";
				function = "gpio";
			};

			config {
				pins = "gpio224";
				drive-strength = <2>;   /* 2 mA */
				bias-pull-down;         /* PULL DOWN */
				input-enable;
			};
		};

		hs3_i2s_sck_active: hs3_i2s_sck_active {
			mux {
				pins = "gpio224";
				function = "hs3_mi2s";
			};

			config {
				pins = "gpio224";
				drive-strength = <8>;   /* 8 mA */
				bias-disable;           /* NO PULL */
				output-high;
			};
		};
	};

	hs3_i2s_ws {
		hs3_i2s_ws_sleep: hs3_i2s_ws_sleep {
			mux {
				pins = "gpio225";
				function = "gpio";
			};

			config {
				pins = "gpio225";
				drive-strength = <2>;   /* 2 mA */
				bias-pull-down;         /* PULL DOWN */
				input-enable;
			};
		};

		hs3_i2s_ws_active: hs3_i2s_ws_active {
			mux {
				pins = "gpio225";
				function = "hs3_mi2s";
			};

			config {
				pins = "gpio225";
				drive-strength = <8>;   /* 8 mA */
				bias-disable;           /* NO PULL */
				output-high;
			};
		};
	};

	hs3_i2s_data0 {
		hs3_i2s_data0_sleep: hs3_i2s_data0_sleep {
			mux {
				pins = "gpio226";
				function = "gpio";
			};

			config {
				pins = "gpio226";
				drive-strength = <2>;   /* 2 mA */
				bias-pull-down;         /* PULL DOWN */
				input-enable;
			};
		};

		hs3_i2s_data0_active: hs3_i2s_data0_active {
			mux {
				pins = "gpio226";
				function = "hs3_mi2s";
			};

			config {
				pins = "gpio226";
				drive-strength = <8>;   /* 8 mA */
				bias-disable;           /* NO PULL */
				output-high;
			};
		};
	};

	hs3_i2s_data1 {
		hs3_i2s_data1_sleep: hs3_i2s_data1_sleep {
			mux {
				pins = "gpio227";
				function = "gpio";
			};

			config {
				pins = "gpio227";
				drive-strength = <2>;   /* 2 mA */
				bias-pull-down;         /* PULL DOWN */
				input-enable;
			};
		};

		hs3_i2s_data1_active: hs3_i2s_data1_active {
			mux {
				pins = "gpio227";
				function = "hs3_mi2s";
			};

			config {
				pins = "gpio227";
				drive-strength = <8>;   /* 8 mA */
				bias-disable;           /* NO PULL */
				input-enable;
			};
		};
	};

	hs4_i2s_sck {
		hs4_i2s_sck_sleep: hs4_i2s_sck_sleep {
			mux {
				pins = "gpio220";
				function = "gpio";
			};

			config {
				pins = "gpio220";
				drive-strength = <2>;   /* 2 mA */
				bias-pull-down;         /* PULL DOWN */
				input-enable;
			};
		};

		hs4_i2s_sck_active: hs4_i2s_sck_active {
			mux {
				pins = "gpio220";
				function = "mi2s1_sck";
			};

			config {
				pins = "gpio220";
				drive-strength = <8>;   /* 8 mA */
				bias-disable;           /* NO PULL */
				output-high;
			};
		};
	};

	hs4_i2s_ws {
		hs4_i2s_ws_sleep: hs4_i2s_ws_sleep {
			mux {
				pins = "gpio221";
				function = "gpio";
			};

			config {
				pins = "gpio221";
				drive-strength = <2>;   /* 2 mA */
				bias-pull-down;         /* PULL DOWN */
				input-enable;
			};
		};

		hs4_i2s_ws_active: hs4_i2s_ws_active {
			mux {
				pins = "gpio221";
				function = "mi2s1_ws";
			};

			config {
				pins = "gpio221";
				drive-strength = <8>;   /* 8 mA */
				bias-disable;           /* NO PULL */
				output-high;
			};
		};
	};

	hs4_i2s_data0 {
		hs4_i2s_data0_sleep: hs4_i2s_data0_sleep {
			mux {
				pins = "gpio222";
				function = "gpio";
			};

			config {
				pins = "gpio222";
				drive-strength = <2>;   /* 2 mA */
				bias-pull-down;         /* PULL DOWN */
				input-enable;
			};
		};

		hs4_i2s_data0_active: hs4_i2s_data0_active {
			mux {
				pins = "gpio222";
				function = "mi2s1_data0";
			};

			config {
				pins = "gpio222";
				drive-strength = <8>;   /* 8 mA */
				bias-disable;           /* NO PULL */
				output-high;
			};
		};
	};

	hs4_i2s_data1 {
		hs4_i2s_data1_sleep: hs4_i2s_data1_sleep {
			mux {
				pins = "gpio223";
				function = "gpio";
			};

			config {
				pins = "gpio223";
				drive-strength = <2>;   /* 2 mA */
				bias-pull-down;         /* PULL DOWN */
				input-enable;
			};
		};

		hs4_i2s_data1_active: hs4_i2s_data1_active {
			mux {
				pins = "gpio223";
				function = "mi2s1_data1";
			};

			config {
				pins = "gpio223";
				drive-strength = <8>;   /* 8 mA */
				bias-disable;           /* NO PULL */
				input-enable;
			};
		};
	};

	hs5_i2s_sck {
		hs5_i2s_sck_sleep: hs5_i2s_sck_sleep {
			mux {
				pins = "gpio212";
				function = "gpio";
			};

			config {
				pins = "gpio212";
				drive-strength = <2>;   /* 2 mA */
				bias-pull-down;         /* PULL DOWN */
				input-enable;
			};
		};

		hs5_i2s_sck_active: hs5_i2s_sck_active {
			mux {
				pins = "gpio212";
				function = "mi2s2_sck";
			};

			config {
				pins = "gpio212";
				drive-strength = <8>;   /* 8 mA */
				bias-disable;           /* NO PULL */
				output-high;
			};
		};
	};

	hs5_i2s_ws {
		hs5_i2s_ws_sleep: hs5_i2s_ws_sleep {
			mux {
				pins = "gpio213";
				function = "gpio";
			};

			config {
				pins = "gpio213";
				drive-strength = <2>;   /* 2 mA */
				bias-pull-down;         /* PULL DOWN */
				input-enable;
			};
		};

		hs5_i2s_ws_active: hs5_i2s_ws_active {
			mux {
				pins = "gpio213";
				function = "mi2s2_ws";
			};

			config {
				pins = "gpio213";
				drive-strength = <8>;   /* 8 mA */
				bias-disable;           /* NO PULL */
				output-high;
			};
		};
	};

	hs5_i2s_data0 {
		hs5_i2s_data0_sleep: hs5_i2s_data0_sleep {
			mux {
				pins = "gpio214";
				function = "gpio";
			};

			config {
				pins = "gpio214";
				drive-strength = <2>;   /* 2 mA */
				bias-pull-down;         /* PULL DOWN */
				input-enable;
			};
		};

		hs5_i2s_data0_active: hs5_i2s_data0_active {
			mux {
				pins = "gpio214";
				function = "mi2s2_data0";
			};

			config {
				pins = "gpio214";
				drive-strength = <8>;   /* 8 mA */
				bias-disable;           /* NO PULL */
				output-high;
			};
		};
	};

	hs5_i2s_data1 {
		hs5_i2s_data1_sleep: hs5_i2s_data1_sleep {
			mux {
				pins = "gpio215";
				function = "gpio";
			};

			config {
				pins = "gpio215";
				drive-strength = <2>;   /* 2 mA */
				bias-pull-down;         /* PULL DOWN */
				input-enable;
			};
		};

		hs5_i2s_data1_active: hs5_i2s_data1_active {
			mux {
				pins = "gpio215";
				function = "mi2s2_data1";
			};

			config {
				pins = "gpio215";
				drive-strength = <8>;   /* 8 mA */
				bias-disable;           /* NO PULL */
				input-enable;
			};
		};
	};
};
